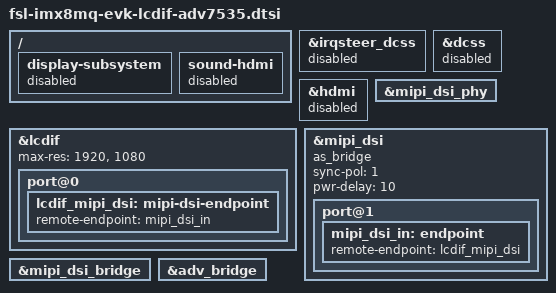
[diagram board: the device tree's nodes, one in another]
/*
 * Copyright 2018 NXP
 *
 * This program is free software; you can redistribute it and/or
 * modify it under the terms of the GNU General Public License
 * as published by the Free Software Foundation; either version 2
 * of the License, or (at your option) any later version.
 *
 * This program is distributed in the hope that it will be useful,
 * but WITHOUT ANY WARRANTY; without even the implied warranty of
 * MERCHANTABILITY or FITNESS FOR A PARTICULAR PURPOSE.  See the
 * GNU General Public License for more details.
 */

/ {
	display-subsystem {
		status = "disabled";
	};

	sound-hdmi {
		status = "disabled";
	};
};

&irqsteer_dcss {
	status = "disabled";
};

&dcss {
	status = "disabled";
};

&hdmi {
	status = "disabled";
};

&lcdif {
	status = "okay";
	max-res = <1920>, <1080>;

	port@0 {
		lcdif_mipi_dsi: mipi-dsi-endpoint {
			remote-endpoint = <&mipi_dsi_in>;
		};
	};
};

&mipi_dsi_phy {
	status = "okay";
};

&mipi_dsi {
	status = "okay";
	as_bridge;
	sync-pol = <1>;
	pwr-delay = <10>;

	port@1 {
		mipi_dsi_in: endpoint {
			remote-endpoint = <&lcdif_mipi_dsi>;
		};
	};
};

&mipi_dsi_bridge {
	status = "okay";
};

&adv_bridge {
	status = "okay";
};
